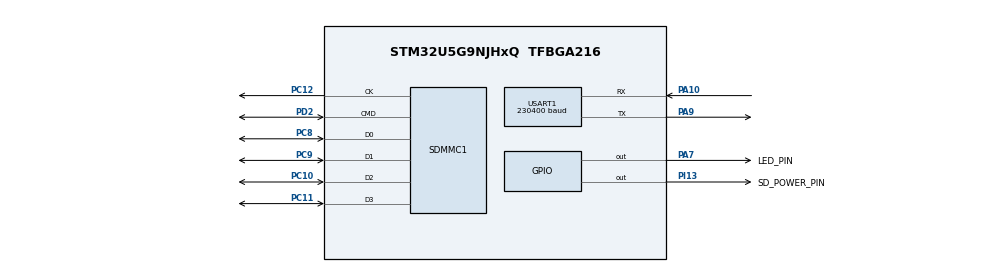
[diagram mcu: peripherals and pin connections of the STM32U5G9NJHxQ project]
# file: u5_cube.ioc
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CORTEX_M33_NS.userName=CORTEX_M33
Mcu.Family=STM32U5
Mcu.Name=STM32U5G9NJHxQ
Mcu.Package=TFBGA216
NVIC.PriorityGroup=NVIC_PRIORITYGROUP_4
NVIC.SDMMC1_IRQn=true\:0\:0\:false\:false\:true\:true\:true\:true
NVIC.USART1_IRQn=true\:0\:0\:false\:false\:true\:true\:true\:true
PA10.Mode=Asynchronous
PA10.Signal=USART1_RX
PA13\ (JTMS/SWDIO).Mode=Serial_Wire
PA13\ (JTMS/SWDIO).Signal=DEBUG_JTMS-SWDIO
PA14\ (JTCK/SWCLK).Mode=Serial_Wire
PA14\ (JTCK/SWCLK).Signal=DEBUG_JTCK-SWCLK
PA7.GPIO_Label=LED_PIN
PA7.Signal=GPIO_Output
PA9.Mode=Asynchronous
PA9.Signal=USART1_TX
PC10.Mode=SD_4_bits_Wide_bus
PC10.Signal=SDMMC1_D2
PC11.Mode=SD_4_bits_Wide_bus
PC11.Signal=SDMMC1_D3
PC12.Mode=SD_4_bits_Wide_bus
PC12.Signal=SDMMC1_CK
PC14-OSC32_IN\ (PC14).Mode=LSE-External-Oscillator
PC14-OSC32_IN\ (PC14).Signal=RCC_OSC32_IN
PC15-OSC32_OUT\ (PC15).Mode=LSE-External-Oscillator
PC15-OSC32_OUT\ (PC15).Signal=RCC_OSC32_OUT
PC8.Mode=SD_4_bits_Wide_bus
PC8.Signal=SDMMC1_D0
PC9.Mode=SD_4_bits_Wide_bus
PC9.Signal=SDMMC1_D1
PD2.Mode=SD_4_bits_Wide_bus
PD2.Signal=SDMMC1_CMD
PH0-OSC_IN\ (PH0).Mode=HSE-External-Oscillator
PH0-OSC_IN\ (PH0).Signal=RCC_OSC_IN
PH1-OSC_OUT\ (PH1).Mode=HSE-External-Oscillator
PH1-OSC_OUT\ (PH1).Signal=RCC_OSC_OUT
PI13.GPIO_Label=SD_POWER_PIN
PI13.PinState=GPIO_PIN_SET
PI13.Signal=GPIO_Output
PWR.PowerMode=PWR_SMPS_SUPPLY
ProjectManager.HeapSize=0x200
ProjectManager.StackSize=0x400
ProjectManager.TargetToolchain=Makefile
RCC.ADCFreq_Value=16000000
RCC.AHBFreq_Value=160000000
RCC.APB1Freq_Value=160000000
RCC.APB1TimFreq_Value=160000000
RCC.APB2Freq_Value=160000000
RCC.APB2TimFreq_Value=160000000
RCC.APB3Freq_Value=160000000
RCC.CortexFreq_Value=160000000
RCC.EPOD_VALUE=16000000
RCC.HCLKFreq_Value=160000000
RCC.HSE_VALUE=16000000
RCC.HSI48_VALUE=48000000
RCC.HSI_VALUE=16000000
RCC.LSIDIV_VALUE=32000
RCC.MSI_VALUE=4000000
RCC.PLL1P=4
RCC.PLL1R=1
RCC.PLLN=10
RCC.PLLSourceVirtual=RCC_PLLSOURCE_HSE
RCC.SYSCLKFreq_VALUE=160000000
RCC.SYSCLKSource=RCC_SYSCLKSOURCE_PLLCLK
RCC.USART1CLockSelectionVirtual=RCC_USART1CLKSOURCE_SYSCLK
RCC.VCOOutputFreq_Value=160000000
USART1.BaudRate=230400
USART1.DMADisableonRxErrorParam=ADVFEATURE_DMA_DISABLEONRXERROR
USART1.FIFOMode=FIFOMODE_ENABLE
USART1.Mode=MODE_TX
USART1.OverrunDisableParam=ADVFEATURE_OVERRUN_DISABLE
USART1.VirtualMode-Asynchronous=VM_ASYNC
VP_ICACHE_VS_ICACHE.Mode=DirectMappedCache
VP_LPBAMQUEUE_VS_QUEUE.Mode=QUEUEMODE
VP_LPBAM_VS_SIG1.Mode=SmartRun
VP_LPBAM_VS_SIG4.Mode=LPDMA1
VP_MEMORYMAP_VS_MEMORYMAP.Mode=CurAppReg
VP_PWR_VS_DBSignals.Mode=DisableDeadBatterySignals
VP_PWR_VS_LPOM.Mode=PowerOptimisation
VP_PWR_VS_SECSignals.Mode=Security/Privilege
board=custom

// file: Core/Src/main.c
/* USER CODE BEGIN Header */
/**
  ******************************************************************************
  * @file           : main.c
  * @brief          : Main program body
  ******************************************************************************
  * @attention
  *
  * Copyright (c) 2024 STMicroelectronics.
  * All rights reserved.
  *
  * This software is licensed under terms that can be found in the LICENSE file
  * in the root directory of this software component.
  * If no LICENSE file comes with this software, it is provided AS-IS.
  *
  ******************************************************************************
  */
/* USER CODE END Header */
#include "main.h"

SD_HandleTypeDef hsd1;

void SystemClock_Config(void);
static void SystemPower_Config(void);
static void MX_GPIO_Init(void);
static void MX_ICACHE_Init(void);
static void MX_USART1_UART_Init(void);
static void MX_SDMMC1_SD_Init(void);
/* USER CODE BEGIN PFP */
extern void main_ll(void);
/* USER CODE END PFP */

/* USER CODE BEGIN 0 */
static void console_uart_tx(uint8_t data) {
    while(LL_USART_IsActiveFlag_TXE_TXFNF(USART1) == 0) {
    }
    LL_USART_TransmitData8(USART1, data);
}

static void console_uart_tx_str(const char* str) {
    while(*str) {
        console_uart_tx(*str++);
    }
}
/* USER CODE END 0 */

int main(void)
{
  /* USER CODE BEGIN 1 */
  main_ll();
  /* USER CODE END 1 */

  /* MCU Configuration--------------------------------------------------------*/

  /* Reset of all peripherals, Initializes the Flash interface and the Systick. */
  HAL_Init();

  /* Enable PWR clock interface */

  LL_AHB3_GRP1_EnableClock(LL_AHB3_GRP1_PERIPH_PWR);

  /* Configure the system clock */
  SystemClock_Config();

  /* Configure the System Power */
  SystemPower_Config();

  /* Initialize all configured peripherals */
  MX_GPIO_Init();
  MX_ICACHE_Init();
  MX_USART1_UART_Init();
  MX_SDMMC1_SD_Init();
  /* USER CODE BEGIN 2 */
  console_uart_tx_str("Start\r\n");
  /* USER CODE END 2 */

  /* Infinite loop */
  while (1)
  {

    /* USER CODE BEGIN 3 */
        console_uart_tx_str("Toggle LED\r\n");
        LL_GPIO_TogglePin(LED_PIN_GPIO_Port, LED_PIN_Pin);
        LL_mDelay(1000);
  }
  /* USER CODE END 3 */
}

void SystemClock_Config(void)
{
  LL_FLASH_SetLatency(LL_FLASH_LATENCY_4);
  while(LL_FLASH_GetLatency()!= LL_FLASH_LATENCY_4)
  {
  }

  LL_PWR_SetRegulVoltageScaling(LL_PWR_REGU_VOLTAGE_SCALE1);
  while (LL_PWR_IsActiveFlag_VOS() == 0)
  {
  }
  LL_RCC_HSE_Enable();

   /* Wait till HSE is ready */
  while(LL_RCC_HSE_IsReady() != 1)
  {
  }

  LL_RCC_PLL1_ConfigDomain_SYS(LL_RCC_PLL1SOURCE_HSE, 1, 10, 1);
  LL_RCC_PLL1_ConfigDomain_SAI(LL_RCC_PLL1SOURCE_HSE, 1, 10, 4);
  LL_RCC_PLL1_EnableDomain_SYS();
  LL_RCC_PLL1_EnableDomain_SAI();
  LL_RCC_SetPll1EPodPrescaler(LL_RCC_PLL1MBOOST_DIV_1);
  LL_RCC_PLL1_SetVCOInputRange(LL_RCC_PLLINPUTRANGE_8_16);
  LL_RCC_PLL1_Enable();

   /* Wait till PLL is ready */
  while(LL_RCC_PLL1_IsReady() != 1)
  {
  }

   /* Intermediate AHB prescaler 2 when target frequency clock is higher than 80 MHz */
  LL_RCC_SetAHBPrescaler(LL_RCC_SYSCLK_DIV_2);

  LL_RCC_SetSysClkSource(LL_RCC_SYS_CLKSOURCE_PLL1);

   /* Wait till System clock is ready */
  while(LL_RCC_GetSysClkSource() != LL_RCC_SYS_CLKSOURCE_STATUS_PLL1)
  {
  }

  /* Insure 1us transition state at intermediate medium speed clock*/
  for (__IO uint32_t i = (160 >> 1); i !=0; i--);

  LL_RCC_SetAHBPrescaler(LL_RCC_SYSCLK_DIV_1);
  LL_RCC_SetAPB1Prescaler(LL_RCC_APB1_DIV_1);
  LL_RCC_SetAPB2Prescaler(LL_RCC_APB2_DIV_1);
  LL_RCC_SetAPB3Prescaler(LL_RCC_APB3_DIV_1);
  LL_SetSystemCoreClock(160000000);

   /* Update the time base */
  if (HAL_InitTick (TICK_INT_PRIORITY) != HAL_OK)
  {
    Error_Handler();
  }
}

/**
  * @brief Power Configuration
  * @retval None
  */
static void SystemPower_Config(void)
{

  /*
   * Disable the internal Pull-Up in Dead Battery pins of UCPD peripheral
   */
  LL_PWR_DisableUCPDDeadBattery();

  /*
   * Switch to SMPS regulator instead of LDO
   */
  LL_PWR_SetRegulatorSupply(LL_PWR_SMPS_SUPPLY);

  while(LL_PWR_IsActiveFlag_REGULATOR()!=1)
  {
  }
}

static void MX_ICACHE_Init(void)
{

  /** Enable instruction cache in 1-way (direct mapped cache)
  */
  LL_ICACHE_SetMode(LL_ICACHE_1WAY);
  LL_ICACHE_Enable();

}

static void MX_SDMMC1_SD_Init(void)
{

  hsd1.Instance = SDMMC1;
  hsd1.Init.ClockEdge = SDMMC_CLOCK_EDGE_RISING;
  hsd1.Init.ClockPowerSave = SDMMC_CLOCK_POWER_SAVE_DISABLE;
  hsd1.Init.BusWide = SDMMC_BUS_WIDE_4B;
  hsd1.Init.HardwareFlowControl = SDMMC_HARDWARE_FLOW_CONTROL_DISABLE;
  hsd1.Init.ClockDiv = 0;
  if (HAL_SD_Init(&hsd1) != HAL_OK)
  {
    Error_Handler();
  }

}

static void MX_USART1_UART_Init(void)
{

  LL_USART_InitTypeDef USART_InitStruct = {0};

  LL_GPIO_InitTypeDef GPIO_InitStruct = {0};

  LL_RCC_SetUSARTClockSource(LL_RCC_USART1_CLKSOURCE_SYSCLK);

  /* Peripheral clock enable */
  LL_APB2_GRP1_EnableClock(LL_APB2_GRP1_PERIPH_USART1);

  LL_AHB2_GRP1_EnableClock(LL_AHB2_GRP1_PERIPH_GPIOA);
  /**USART1 GPIO Configuration
  PA10   ------> USART1_RX
  PA9   ------> USART1_TX
  */
  GPIO_InitStruct.Pin = LL_GPIO_PIN_10|LL_GPIO_PIN_9;
  GPIO_InitStruct.Mode = LL_GPIO_MODE_ALTERNATE;
  GPIO_InitStruct.Speed = LL_GPIO_SPEED_FREQ_LOW;
  GPIO_InitStruct.OutputType = LL_GPIO_OUTPUT_PUSHPULL;
  GPIO_InitStruct.Pull = LL_GPIO_PULL_NO;
  GPIO_InitStruct.Alternate = LL_GPIO_AF_7;
  LL_GPIO_Init(GPIOA, &GPIO_InitStruct);

  /* USART1 interrupt Init */
  NVIC_SetPriority(USART1_IRQn, NVIC_EncodePriority(NVIC_GetPriorityGrouping(),0, 0));
  NVIC_EnableIRQ(USART1_IRQn);

  USART_InitStruct.PrescalerValue = LL_USART_PRESCALER_DIV1;
  USART_InitStruct.BaudRate = 230400;
  USART_InitStruct.DataWidth = LL_USART_DATAWIDTH_8B;
  USART_InitStruct.StopBits = LL_USART_STOPBITS_1;
  USART_InitStruct.Parity = LL_USART_PARITY_NONE;
  USART_InitStruct.TransferDirection = LL_USART_DIRECTION_TX;
  USART_InitStruct.HardwareFlowControl = LL_USART_HWCONTROL_NONE;
  USART_InitStruct.OverSampling = LL_USART_OVERSAMPLING_16;
  LL_USART_Init(USART1, &USART_InitStruct);
  LL_USART_SetTXFIFOThreshold(USART1, LL_USART_FIFOTHRESHOLD_1_8);
  LL_USART_SetRXFIFOThreshold(USART1, LL_USART_FIFOTHRESHOLD_1_8);
  LL_USART_EnableFIFO(USART1);
  LL_USART_DisableOverrunDetect(USART1);
  LL_USART_DisableDMADeactOnRxErr(USART1);
  LL_USART_ConfigAsyncMode(USART1);
  LL_USART_Enable(USART1);

}

static void MX_GPIO_Init(void)
{
  LL_GPIO_InitTypeDef GPIO_InitStruct = {0};

  /* GPIO Ports Clock Enable */
  LL_AHB2_GRP1_EnableClock(LL_AHB2_GRP1_PERIPH_GPIOC);
  LL_AHB2_GRP1_EnableClock(LL_AHB2_GRP1_PERIPH_GPIOA);
  LL_AHB2_GRP1_EnableClock(LL_AHB2_GRP1_PERIPH_GPIOD);
  LL_AHB2_GRP1_EnableClock(LL_AHB2_GRP1_PERIPH_GPIOI);
  LL_AHB2_GRP1_EnableClock(LL_AHB2_GRP1_PERIPH_GPIOH);

  /**/
  LL_GPIO_SetOutputPin(SD_POWER_PIN_GPIO_Port, SD_POWER_PIN_Pin);

  /**/
  LL_GPIO_ResetOutputPin(LED_PIN_GPIO_Port, LED_PIN_Pin);

  /**/
  GPIO_InitStruct.Pin = SD_POWER_PIN_Pin;
  GPIO_InitStruct.Mode = LL_GPIO_MODE_OUTPUT;
  GPIO_InitStruct.Speed = LL_GPIO_SPEED_FREQ_LOW;
  GPIO_InitStruct.OutputType = LL_GPIO_OUTPUT_PUSHPULL;
  GPIO_InitStruct.Pull = LL_GPIO_PULL_NO;
  LL_GPIO_Init(SD_POWER_PIN_GPIO_Port, &GPIO_InitStruct);

  /**/
  GPIO_InitStruct.Pin = LED_PIN_Pin;
  GPIO_InitStruct.Mode = LL_GPIO_MODE_OUTPUT;
  GPIO_InitStruct.Speed = LL_GPIO_SPEED_FREQ_LOW;
  GPIO_InitStruct.OutputType = LL_GPIO_OUTPUT_PUSHPULL;
  GPIO_InitStruct.Pull = LL_GPIO_PULL_NO;
  LL_GPIO_Init(LED_PIN_GPIO_Port, &GPIO_InitStruct);

}

void Error_Handler(void)
{
    __disable_irq();
    while(1) {
    }
}
